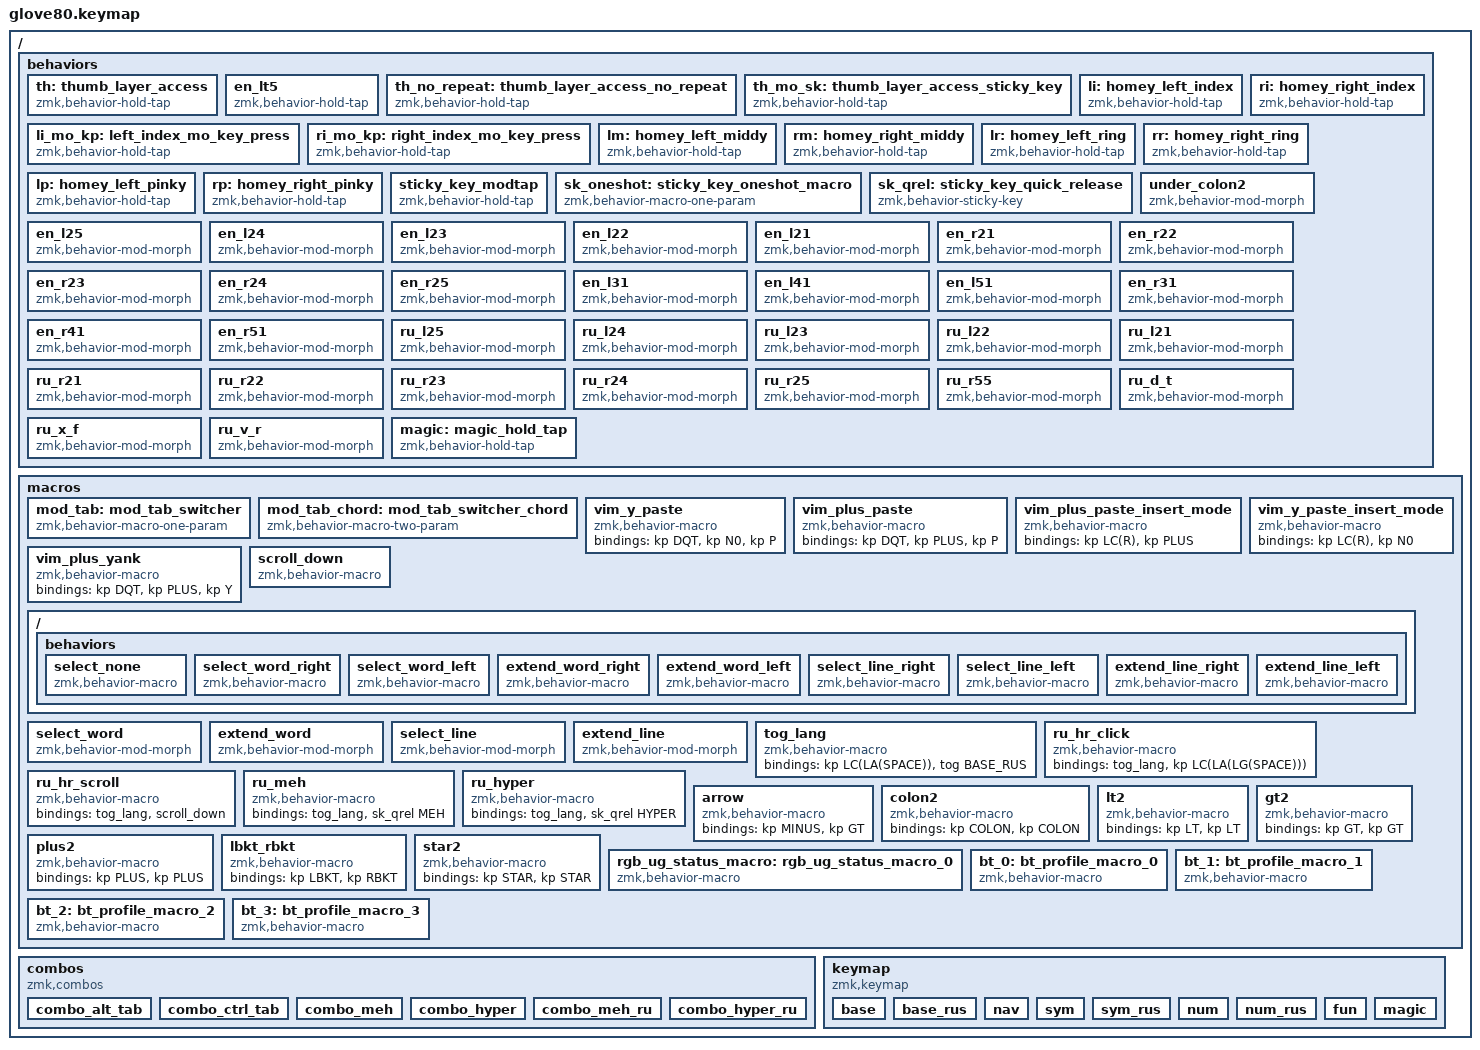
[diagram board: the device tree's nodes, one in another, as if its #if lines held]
/*
 * Copyright (c) 2020 The ZMK Contributors
 *
 * SPDX-License-Identifier: MIT
 */

#include <behaviors.dtsi>
#include <dt-bindings/zmk/keys.h>
#include <dt-bindings/zmk/bt.h>
#include <dt-bindings/zmk/ext_power.h>
#include <dt-bindings/zmk/outputs.h>
#include <dt-bindings/zmk/rgb.h>

#define HYPER LC(LS(LG(LALT)))
#define MEH LC(LG(LALT))

// layers
#define BASE 0
#define BASE_RUS 1
#define NAV 2
#define SYM 3
#define SYM_RUS 4
#define NUM 5
#define NUM_RUS 6
#define FUN 7
#define MAGIC 8

#ifndef OPERATING_SYSTEM
//#define OPERATING_SYSTEM 'L' // linux
#define OPERATING_SYSTEM 'M' // macos
//#define OPERATING_SYSTEM 'W' // windows
#endif
#if OPERATING_SYSTEM == 'M'
    #define _C      LG
    #define _A_TAB  LGUI
    #define _G_TAB  LALT
    #define _REDO   _C(LS(Z))
    #define _POWER  K_POWER
    #define _W      LA
    #define _HOME   _C(LEFT)
    #define _END    _C(RIGHT)
#else
    #define _C      LC
    #define _A_TAB  LALT
    #define _G_TAB  LGUI
    #define _REDO   _C(Y)
    #define _POWER  C_POWER
    #define _W      _C
    #define _HOME   HOME
    #define _END    END
#endif
#define _SLEEP      C_SLEEP
#if OPERATING_SYSTEM == 'W'
    #define _LOCK   LG(L)
#elif OPERATING_SYSTEM == 'M'
    #define _LOCK   _C(LC(Q))
#elif OPERATING_SYSTEM == 'L'
    #define _LOCK   K_LOCK
#endif
#define _UNDO       _C(Z)
#define _CUT        _C(X)
#define _COPY       _C(C)
#define _PASTE      _C(V)
#define _FIND       _C(F)
#define _FIND_NEXT  _C(G)
#define _FIND_PREV  _C(LS(G))


//
// The *_MOD specify which modifiers are used by home row mod keys.
//
#define RING_MOD LALT
#define INDEX_MOD LSHFT
#if OPERATING_SYSTEM == 'M'
  #define PINKY_MOD LCTRL
  #define MIDDY_MOD LGUI
#else
  #define PINKY_MOD LGUI
  #define MIDDY_MOD LCTRL
#endif

/* #define for key positions */
#define POS_LH_T1 52
#define POS_LH_T2 53
#define POS_LH_T3 54
#define POS_LH_T4 69
#define POS_LH_T5 70
#define POS_LH_T6 71
#define POS_LH_C1R2 15
#define POS_LH_C1R3 27
#define POS_LH_C1R4 39
#define POS_LH_C1R5 51
#define POS_LH_C2R1 4
#define POS_LH_C2R2 14
#define POS_LH_C2R3 26
#define POS_LH_C2R4 38
#define POS_LH_C2R5 50
#define POS_LH_C2R6 68
#define POS_LH_C3R1 3
#define POS_LH_C3R2 13
#define POS_LH_C3R3 25
#define POS_LH_C3R4 37
#define POS_LH_C3R5 49
#define POS_LH_C3R6 67
#define POS_LH_C4R1 2
#define POS_LH_C4R2 12
#define POS_LH_C4R3 24
#define POS_LH_C4R4 36
#define POS_LH_C4R5 48
#define POS_LH_C4R6 66
#define POS_LH_C5R1 1
#define POS_LH_C5R2 11
#define POS_LH_C5R3 23
#define POS_LH_C5R4 35
#define POS_LH_C5R5 47
#define POS_LH_C5R6 65
#define POS_LH_C6R1 0
#define POS_LH_C6R2 10
#define POS_LH_C6R3 22
#define POS_LH_C6R4 34
#define POS_LH_C6R5 46
#define POS_LH_C6R6 64
#define POS_RH_T1 57
#define POS_RH_T2 56
#define POS_RH_T3 55
#define POS_RH_T4 74
#define POS_RH_T5 73
#define POS_RH_T6 72
#define POS_RH_C1R2 16
#define POS_RH_C1R3 28
#define POS_RH_C1R4 40
#define POS_RH_C1R5 58
#define POS_RH_C2R1 5
#define POS_RH_C2R2 17
#define POS_RH_C2R3 29
#define POS_RH_C2R4 41
#define POS_RH_C2R5 59
#define POS_RH_C2R6 75
#define POS_RH_C3R1 6
#define POS_RH_C3R2 18
#define POS_RH_C3R3 30
#define POS_RH_C3R4 42
#define POS_RH_C3R5 60
#define POS_RH_C3R6 76
#define POS_RH_C4R1 7
#define POS_RH_C4R2 19
#define POS_RH_C4R3 31
#define POS_RH_C4R4 43
#define POS_RH_C4R5 61
#define POS_RH_C4R6 77
#define POS_RH_C5R1 8
#define POS_RH_C5R2 20
#define POS_RH_C5R3 32
#define POS_RH_C5R4 44
#define POS_RH_C5R5 62
#define POS_RH_C5R6 78
#define POS_RH_C6R1 9
#define POS_RH_C6R2 21
#define POS_RH_C6R3 33
#define POS_RH_C6R4 45
#define POS_RH_C6R5 63
#define POS_RH_C6R6 79

/ {

    //
    // TAPPING_RESOLUTION specifies the maximum speed at which the keyboard
    // confuses your taps as being holds when you type on home row mod keys.
    // When you lower this value, the same confusion should still occur; but
    // when you raise this value, you should be able to type normally again.
    //
    #define TAPPING_RESOLUTION 150

    //
    // HOMEY_HOLDING_TYPE defines the flavor of ZMK hold-tap behavior to use
    // for the pinky, ring, and middle fingers (which are assigned to Super,
    // Alt, and Ctrl respectively in the Miryoku system) on home row keys.
    //
    #define HOMEY_HOLDING_TYPE "tap-preferred"
    #define INDEX_HOLDING_TYPE HOMEY_HOLDING_TYPE
    #define MIDDY_HOLDING_TYPE HOMEY_HOLDING_TYPE
    #define RING_HOLDING_TYPE  HOMEY_HOLDING_TYPE
    #define PINKY_HOLDING_TYPE HOMEY_HOLDING_TYPE

    #define THUMB_HOLDING_TYPE "balanced"

    //
    // HOMEY_HOLDING_TIME defines how long you need to hold (milliseconds)
    // home row mod keys in order to send their modifiers to the computer
    // (i.e. "register" them) for mod-click mouse usage (e.g. Ctrl-Click).
    //
    #define HOMEY_HOLDING_TIME (TAPPING_RESOLUTION + 90)
    #define INDEX_HOLDING_TIME (TAPPING_RESOLUTION + 20)
    #define MIDDY_HOLDING_TIME (TAPPING_RESOLUTION + 60)
    #define RING_HOLDING_TIME  (TAPPING_RESOLUTION + 90)
    #define PINKY_HOLDING_TIME (TAPPING_RESOLUTION + 110)

    #define THUMB_HOLDING_TIME (TAPPING_RESOLUTION + 50)

    //
    // HOMEY_STREAK_DECAY defines how long you need to wait (milliseconds)
    // after typing before you can use home row mods again.  It prevents
    // unintended activation of home row mods when you're actively typing.
    //
    #define HOMEY_STREAK_DECAY TAPPING_RESOLUTION
    #define INDEX_STREAK_DECAY (TAPPING_RESOLUTION - 50)
    #define MIDDY_STREAK_DECAY HOMEY_STREAK_DECAY 
    #define RING_STREAK_DECAY  HOMEY_STREAK_DECAY 
    #define PINKY_STREAK_DECAY HOMEY_STREAK_DECAY 

    #define _STREAK_DECAY HOMEY_STREAK_DECAY 

    //
    // HOMEY_REPEAT_DECAY defines how much time you have left (milliseconds)
    // after tapping a key to hold it again in order to make it auto-repeat.
    //
    #define HOMEY_REPEAT_DECAY (TAPPING_RESOLUTION + 150)
    #define INDEX_REPEAT_DECAY HOMEY_REPEAT_DECAY
    #define MIDDY_REPEAT_DECAY HOMEY_REPEAT_DECAY
    #define RING_REPEAT_DECAY  HOMEY_REPEAT_DECAY
    #define PINKY_REPEAT_DECAY HOMEY_REPEAT_DECAY

    #define THUMB_REPEAT_DECAY (TAPPING_RESOLUTION + 150)

    //
    // Glove80 key positions index for positional hold-tap
    // - https://discord.com/channels/877392805654306816/937645688244826154/1066713913351221248
    // - https://media.discordapp.net/attachments/937645688244826154/1066713913133121556/image.png
    //
    // |------------------------|------------------------|
    // | LEFT_HAND_KEYS         |        RIGHT_HAND_KEYS |
    // |                        |                        |
    // |  0  1  2  3  4         |          5  6  7  8  9 |
    // | 10 11 12 13 14 15      |      16 17 18 19 20 21 |
    // | 22 23 24 25 26 27      |      28 29 30 31 32 33 |
    // | 34 35 36 37 38 39      |      40 41 42 43 44 45 |
    // | 46 47 48 49 50 51      |      58 59 60 61 62 63 |
    // | 64 65 66 67 68         |         75 76 77 78 79 |
    // |                69 52   |   57 74                |
    // |                 70 53  |  56 73                 |
    // |                  71 54 | 55 72                  |
    // |------------------------|------------------------|
    //
    #define LEFT_HAND_KEYS      \
          0  1  2  3  4         \
         10 11 12 13 14 15      \
         22 23 24 25 26 27      \
         34 35 36 37 38 39      \
         46 47 48 49 50 51      \
         64 65 66 67 68
    #define RIGHT_HAND_KEYS     \
                                           5  6  7  8  9 \
                                       16 17 18 19 20 21 \
                                       28 29 30 31 32 33 \
                                       40 41 42 43 44 45 \
                                       58 59 60 61 62 63 \
                                          75 76 77 78 79
    #define THUMB_KEYS          \
                        69 52       57 74                \
                         70 53     56 73                 \
                          71 54   55 72

    // Rus symbols
    #define COLON_RUS CARET
    #define DOT_RUS SLASH
    #define COMMA_RUS LS(SLASH)
    #define SEMI_RUS LS(N4)
    #define SQT_RUS RA(O)
    #define DQT_RUS LS(N2)
    #define GRAVE_RUS LC(RA(GRAVE))
    #define LBRC_RUS LS(RA(N9))
    #define RBRC_RUS LS(RA(N0))
    #define LBKT_RUS RA(GRAVE)
    #define RBKT_RUS LS(RA(GRAVE))
    #define QMARK_RUS LS(N7)
    #define AT_RUS RA(N2)
    #define HASH_RUS RA(N3)
    #define EXCL_RUS EXCL
    #define LT_RUS LS(RA(COMMA))
    #define GT_RUS LS(RA(DOT))
    #define AMPS_RUS RA(N7)
    #define CARET_RUS RA(N6)
    #define PIPE_RUS LS(RA(BSLH))
    #define PLUS_RUS PLUS
    #define DLLR_RUS RA(N4)
    #define MINUS_RUS MINUS
    #define STAR_RUS STAR
    #define SLASH_RUS LS(BSLH)
    #define TILDE_RUS D // did not find a way to get TILDE on rus
    #define PRCNT_RUS PRCNT
    #define BSLH_RUS BSLH
    #define EQUAL_RUS EQUAL
    #define UNDER_RUS UNDER
    #define LPAR_RUS LPAR
    #define RPAR_RUS RPAR
    #define MID_DASH_RUS RA(MINUS) 
    #define LON_DASH_RUS LS(RA(MINUS))
    #define LQT1_RUS RA(RBKT)
    #define RQT1_RUS LS(RA(RBKT))
    #define LQT2_RUS LS(RA(O))
    #define RQT2_RUS RA(LBKT)
    #define NO_RUS LS(N3)

    behaviors {
        th: thumb_layer_access {
            compatible = "zmk,behavior-hold-tap";
            flavor = THUMB_HOLDING_TYPE;
            tapping-term-ms = <THUMB_HOLDING_TIME>;
            quick-tap-ms = <THUMB_REPEAT_DECAY>; // enable repeat
            #binding-cells = <2>;
            bindings = <&mo>, <&kp>;
        };

        en_lt5: en_lt5 {
            compatible = "zmk,behavior-hold-tap";
            flavor = THUMB_HOLDING_TYPE;
            tapping-term-ms = <THUMB_HOLDING_TIME>;
            #binding-cells = <2>;
            bindings = <&mo>, <&under_colon2>;
        };

        th_no_repeat: thumb_layer_access_no_repeat {
            compatible = "zmk,behavior-hold-tap";
            flavor = THUMB_HOLDING_TYPE;
            tapping-term-ms = <THUMB_HOLDING_TIME>;
            #binding-cells = <2>;
            bindings = <&mo>, <&kp>;
        };

        th_mo_sk: thumb_layer_access_sticky_key {
            compatible = "zmk,behavior-hold-tap";
            flavor = THUMB_HOLDING_TYPE;
            tapping-term-ms = <THUMB_HOLDING_TIME>;
            #binding-cells = <2>;
            bindings = <&mo>, <&sk_qrel>;
        };

        li: homey_left_index {
            compatible = "zmk,behavior-hold-tap";
            flavor = INDEX_HOLDING_TYPE;
            hold-trigger-key-positions = <RIGHT_HAND_KEYS THUMB_KEYS>;
            hold-trigger-on-release; // wait for other home row mods
            tapping-term-ms = <INDEX_HOLDING_TIME>;
            quick-tap-ms = <INDEX_REPEAT_DECAY>;
            require-prior-idle-ms = <INDEX_STREAK_DECAY>;
            #binding-cells = <2>;
            bindings = <&kp>, <&kp>;
        };

        li_mo_kp: left_index_mo_key_press {
            compatible = "zmk,behavior-hold-tap";
            flavor = INDEX_HOLDING_TYPE;
            hold-trigger-key-positions = <RIGHT_HAND_KEYS THUMB_KEYS>;
            hold-trigger-on-release; // wait for other home row mods
            tapping-term-ms = <INDEX_HOLDING_TIME>;
            quick-tap-ms = <INDEX_REPEAT_DECAY>;
            require-prior-idle-ms = <INDEX_STREAK_DECAY>;
            #binding-cells = <2>;
            bindings = <&mo>, <&kp>;
        };

        ri: homey_right_index {
            compatible = "zmk,behavior-hold-tap";
            flavor = INDEX_HOLDING_TYPE;
            hold-trigger-key-positions = <LEFT_HAND_KEYS THUMB_KEYS>;
            hold-trigger-on-release; // wait for other home row mods
            tapping-term-ms = <INDEX_HOLDING_TIME>;
            quick-tap-ms = <INDEX_REPEAT_DECAY>;
            require-prior-idle-ms = <INDEX_STREAK_DECAY>;
            #binding-cells = <2>;
            bindings = <&kp>, <&kp>;
        };

        ri_mo_kp: right_index_mo_key_press {
            compatible = "zmk,behavior-hold-tap";
            flavor = INDEX_HOLDING_TYPE;
            hold-trigger-key-positions = <LEFT_HAND_KEYS THUMB_KEYS>;
            hold-trigger-on-release; // wait for other home row mods
            tapping-term-ms = <INDEX_HOLDING_TIME>;
            quick-tap-ms = <INDEX_REPEAT_DECAY>;
            require-prior-idle-ms = <INDEX_STREAK_DECAY>;
            #binding-cells = <2>;
            bindings = <&mo>, <&kp>;
        };

        lm: homey_left_middy {
            compatible = "zmk,behavior-hold-tap";
            flavor = MIDDY_HOLDING_TYPE;
            hold-trigger-key-positions = <RIGHT_HAND_KEYS THUMB_KEYS>;
            hold-trigger-on-release; // wait for other home row mods
            tapping-term-ms = <MIDDY_HOLDING_TIME>;
            quick-tap-ms = <MIDDY_REPEAT_DECAY>;
            require-prior-idle-ms = <MIDDY_STREAK_DECAY>;
            #binding-cells = <2>;
            bindings = <&kp>, <&kp>;
        };

        rm: homey_right_middy {
            compatible = "zmk,behavior-hold-tap";
            flavor = MIDDY_HOLDING_TYPE;
            hold-trigger-key-positions = <LEFT_HAND_KEYS THUMB_KEYS>;
            hold-trigger-on-release; // wait for other home row mods
            tapping-term-ms = <MIDDY_HOLDING_TIME>;
            quick-tap-ms = <MIDDY_REPEAT_DECAY>;
            require-prior-idle-ms = <MIDDY_STREAK_DECAY>;
            #binding-cells = <2>;
            bindings = <&kp>, <&kp>;
        };

        lr: homey_left_ring {
            compatible = "zmk,behavior-hold-tap";
            flavor = RING_HOLDING_TYPE;
            hold-trigger-key-positions = <RIGHT_HAND_KEYS THUMB_KEYS>;
            hold-trigger-on-release; // wait for other home row mods
            tapping-term-ms = <RING_HOLDING_TIME>;
            quick-tap-ms = <RING_REPEAT_DECAY>;
            require-prior-idle-ms = <RING_STREAK_DECAY>;
            #binding-cells = <2>;
            bindings = <&kp>, <&kp>;
        };

        rr: homey_right_ring {
            compatible = "zmk,behavior-hold-tap";
            flavor = RING_HOLDING_TYPE;
            hold-trigger-key-positions = <LEFT_HAND_KEYS THUMB_KEYS>;
            hold-trigger-on-release; // wait for other home row mods
            tapping-term-ms = <RING_HOLDING_TIME>;
            quick-tap-ms = <RING_REPEAT_DECAY>;
            require-prior-idle-ms = <RING_STREAK_DECAY>;
            #binding-cells = <2>;
            bindings = <&kp>, <&kp>;
        };

        lp: homey_left_pinky {
            compatible = "zmk,behavior-hold-tap";
            flavor = PINKY_HOLDING_TYPE;
            hold-trigger-key-positions = <RIGHT_HAND_KEYS THUMB_KEYS>;
            hold-trigger-on-release; // wait for other home row mods
            tapping-term-ms = <PINKY_HOLDING_TIME>;
            quick-tap-ms = <PINKY_REPEAT_DECAY>;
            require-prior-idle-ms = <PINKY_STREAK_DECAY>;
            #binding-cells = <2>;
            bindings = <&kp>, <&kp>;
            // shift forgiveness
            //hold-while-undecided; // requires 24.08-beta1 or newer firmware, if the firmware is older, it fails
            retro-tap; // tap on standalone hold
        };

        rp: homey_right_pinky {
            compatible = "zmk,behavior-hold-tap";
            flavor = PINKY_HOLDING_TYPE;
            hold-trigger-key-positions = <LEFT_HAND_KEYS THUMB_KEYS>;
            hold-trigger-on-release; // wait for other home row mods
            tapping-term-ms = <PINKY_HOLDING_TIME>;
            quick-tap-ms = <PINKY_REPEAT_DECAY>;
            require-prior-idle-ms = <PINKY_STREAK_DECAY>;
            #binding-cells = <2>;
            bindings = <&kp>, <&kp>;
            // shift forgiveness
            //hold-while-undecided; // requires 24.08-beta1 or newer firmware
            retro-tap; // tap on standalone hold
        };

        //////////////////////////////////////////////////////////////////////////
        //
        // &sk (sticky key) variant that is truly one-shot
        //
        //////////////////////////////////////////////////////////////////////////

        //
        // STICKY_1SHOT_DECAY defines how much time you have left (milliseconds)
        // after tapping a sticky key before it expires (won't apply to next tap).
        //
        #ifndef STICKY_1SHOT_DECAY
        #define STICKY_1SHOT_DECAY 500
        #endif

        //
        // STICKY_HOLDING_TIME defines how long you need to hold (milliseconds)
        // sticky one-shot keys in order to trigger their hold (not tap) action.
        //
        #ifndef STICKY_HOLDING_TIME
        #define STICKY_HOLDING_TIME (TAPPING_RESOLUTION + 50)
        #endif

        sticky_key_modtap: sticky_key_modtap {
            compatible = "zmk,behavior-hold-tap";
            flavor = "tap-preferred";
            tapping-term-ms = <STICKY_HOLDING_TIME>;
            #binding-cells = <2>;
            bindings = <&kp>, <&sk_oneshot>;
        };
        sk_oneshot: sticky_key_oneshot_macro {
            compatible = "zmk,behavior-macro-one-param";
            wait-ms = <0>;
            tap-ms = <0>;
            #binding-cells = <1>;
            bindings
                = <&macro_param_1to1>
                , <&macro_tap &sk_qrel MACRO_PLACEHOLDER>
                ;
        };
        sk_qrel: sticky_key_quick_release {
            compatible = "zmk,behavior-sticky-key";
            #binding-cells = <1>;
            bindings = <&kp>;
            release-after-ms = <STICKY_1SHOT_DECAY>;
            quick-release;
            ignore-modifiers;
        };


        //
        // Custom shifted pairs for the Engram layout
        // - https://engram.dev/
        // - https://sunaku.github.io/engram-keyboard-layout.html
        //

        under_colon2: under_colon2 {
            compatible = "zmk,behavior-mod-morph";
            #binding-cells = <0>;
            bindings = <&kp UNDER>, <&colon2>;
            mods = <(MOD_LSFT|MOD_RSFT)>;
        };

        en_l25: en_l25 {
            compatible = "zmk,behavior-mod-morph";
            #binding-cells = <0>;
            bindings = <&kp LT>, <&kp CARET>;
            mods = <(MOD_LSFT|MOD_RSFT)>;
        };

        en_l24: en_l24 {
            compatible = "zmk,behavior-mod-morph";
            #binding-cells = <0>;
            bindings = <&kp LPAR>, <&kp AT>;
            mods = <(MOD_LSFT|MOD_RSFT)>;
        };

        en_l23: en_l23 {
            compatible = "zmk,behavior-mod-morph";
            #binding-cells = <0>;
            bindings = <&kp RPAR>, <&kp HASH>;
            mods = <(MOD_LSFT|MOD_RSFT)>;
        };

        en_l22: en_l22 {
            compatible = "zmk,behavior-mod-morph";
            #binding-cells = <0>;
            bindings = <&kp GT>, <&kp BSLH>;
            mods = <(MOD_LSFT|MOD_RSFT)>;
        };

        en_l21: en_l21 {
            compatible = "zmk,behavior-mod-morph";
            #binding-cells = <0>;
            bindings = <&kp PIPE>, <&star2>;
            mods = <(MOD_LSFT|MOD_RSFT)>;
        };

        en_r21: en_r21 {
            compatible = "zmk,behavior-mod-morph";
            #binding-cells = <0>;
            bindings = <&kp AMPS>, <&plus2>;
            mods = <(MOD_LSFT|MOD_RSFT)>;
        };

        en_r22: en_r22 {
            compatible = "zmk,behavior-mod-morph";
            #binding-cells = <0>;
            bindings = <&kp LBKT>, <&kp PRCNT>;
            mods = <(MOD_LSFT|MOD_RSFT)>;
        };

        en_r23: en_r23 {
            compatible = "zmk,behavior-mod-morph";
            #binding-cells = <0>;
            bindings = <&kp LBRC>, <&kp TILDE>;
            mods = <(MOD_LSFT|MOD_RSFT)>;
        };

        en_r24: en_r24 {
            compatible = "zmk,behavior-mod-morph";
            #binding-cells = <0>;
            bindings = <&kp RBRC>, <&kp GRAVE>;
            mods = <(MOD_LSFT|MOD_RSFT)>;
        };

        en_r25: en_r25 {
            compatible = "zmk,behavior-mod-morph";
            #binding-cells = <0>;
            bindings = <&kp RBKT>, <&kp DLLR>;
            mods = <(MOD_LSFT|MOD_RSFT)>;
        };

        en_l31: en_l31 {
            compatible = "zmk,behavior-mod-morph";
            #binding-cells = <0>;
            bindings = <&kp SLASH>, <&kp STAR>;
            mods = <(MOD_LSFT|MOD_RSFT)>;
        };

        en_l41: en_l41 {
            compatible = "zmk,behavior-mod-morph";
            #binding-cells = <0>;
            bindings = <&kp COMMA>, <&kp SEMI>;
            mods = <(MOD_LSFT|MOD_RSFT)>;
        };

        en_l51: en_l51 {
            compatible = "zmk,behavior-mod-morph";
            #binding-cells = <0>;
            bindings = <&kp QMARK>, <&kp EXCL>;
            mods = <(MOD_LSFT|MOD_RSFT)>;
        };

        en_r31: en_r31 {
            compatible = "zmk,behavior-mod-morph";
            #binding-cells = <0>;
            bindings = <&kp MINUS>, <&kp PLUS>;
            mods = <(MOD_LSFT|MOD_RSFT)>;
        };

        en_r41: en_r41 {
            compatible = "zmk,behavior-mod-morph";
            #binding-cells = <0>;
            bindings = <&kp DOT>, <&kp COLON>;
            mods = <(MOD_LSFT|MOD_RSFT)>;
        };

        en_r51: en_r51 {
            compatible = "zmk,behavior-mod-morph";
            #binding-cells = <0>;
            bindings = <&kp SQT>, <&kp DQT>;
            mods = <(MOD_LSFT|MOD_RSFT)>;
        };

        ru_l25: ru_l25 {
            compatible = "zmk,behavior-mod-morph";
            #binding-cells = <0>;
            bindings = <&kp HASH_RUS>, <&kp AT_RUS>;
            mods = <(MOD_LSFT|MOD_RSFT)>;
        };

        ru_l24: ru_l24 {
            compatible = "zmk,behavior-mod-morph";
            #binding-cells = <0>;
            bindings = <&kp LPAR_RUS>, <&kp PRCNT_RUS>;
            mods = <(MOD_LSFT|MOD_RSFT)>;
        };

        ru_l23: ru_l23 {
            compatible = "zmk,behavior-mod-morph";
            #binding-cells = <0>;
            bindings = <&kp RPAR_RUS>, <&kp NO_RUS>;
            mods = <(MOD_LSFT|MOD_RSFT)>;
        };

        ru_l22: ru_l22 {
            compatible = "zmk,behavior-mod-morph";
            #binding-cells = <0>;
            bindings = <&kp QMARK_RUS>, <&kp EXCL_RUS>;
            mods = <(MOD_LSFT|MOD_RSFT)>;
        };

        ru_l21: ru_l21 {
            compatible = "zmk,behavior-mod-morph";
            #binding-cells = <0>;
            bindings = <&kp SLASH_RUS>, <&kp STAR_RUS>;
            mods = <(MOD_LSFT|MOD_RSFT)>;
        };

        ru_r21: ru_r21 {
            compatible = "zmk,behavior-mod-morph";
            #binding-cells = <0>;
            bindings = <&kp MINUS_RUS>, <&kp PLUS_RUS>;
            mods = <(MOD_LSFT|MOD_RSFT)>;
        };

        ru_r22: ru_r22 {
            compatible = "zmk,behavior-mod-morph";
            #binding-cells = <0>;
            bindings = <&kp COLON_RUS>, <&kp SEMI_RUS>;
            mods = <(MOD_LSFT|MOD_RSFT)>;
        };

        ru_r23: ru_r23 {
            compatible = "zmk,behavior-mod-morph";
            #binding-cells = <0>;
            bindings = <&kp LQT1_RUS>, <&kp LQT2_RUS>;
            mods = <(MOD_LSFT|MOD_RSFT)>;
        };

        ru_r24: ru_r24 {
            compatible = "zmk,behavior-mod-morph";
            #binding-cells = <0>;
            bindings = <&kp RQT1_RUS>, <&kp RQT2_RUS>;
            mods = <(MOD_LSFT|MOD_RSFT)>;
        };

        ru_r25: ru_r25 {
            compatible = "zmk,behavior-mod-morph";
            #binding-cells = <0>;
            bindings = <&kp N0>, <&kp HASH_RUS>;
            mods = <(MOD_LSFT|MOD_RSFT)>;
        };

        ru_r55: ru_r55 {
            compatible = "zmk,behavior-mod-morph";
            #binding-cells = <0>;
            bindings = <&kp COMMA_RUS>, <&kp SEMI_RUS>;
            mods = <(MOD_LSFT|MOD_RSFT)>;
        };

        ru_d_t: ru_d_t {
            compatible = "zmk,behavior-mod-morph";
            #binding-cells = <0>;
            bindings = <&kp D>, <&kp T>;
            mods = <(MOD_LGUI|MOD_RGUI|MOD_LCTL|MOD_RCTL)>;
            keep-mods = <(MOD_LGUI|MOD_RGUI|MOD_LCTL|MOD_RCTL)>;
        };

        ru_x_f: ru_x_f {
            compatible = "zmk,behavior-mod-morph";
            #binding-cells = <0>;
            bindings = <&kp X>, <&kp F>;
            mods = <(MOD_LGUI|MOD_RGUI|MOD_LCTL|MOD_RCTL)>;
            keep-mods = <(MOD_LGUI|MOD_RGUI|MOD_LCTL|MOD_RCTL)>;
        };

        ru_v_r: ru_v_r {
            compatible = "zmk,behavior-mod-morph";
            #binding-cells = <0>;
            bindings = <&kp V>, <&kp R>;
            mods = <(MOD_LGUI|MOD_RGUI|MOD_LCTL|MOD_RCTL)>;
            keep-mods = <(MOD_LGUI|MOD_RGUI|MOD_LCTL|MOD_RCTL)>;
        };

        magic: magic_hold_tap {
            compatible = "zmk,behavior-hold-tap";
            label = "MAGIC_HOLD_TAP";
            #binding-cells = <2>;
            flavor = "tap-preferred";
            tapping-term-ms = <200>;
            bindings = <&mo>, <&rgb_ug_status_macro>;
        };
    };

    macros {
        //
        // Mod+Tab application switcher - hold this down to keep menu open
        //
        mod_tab: mod_tab_switcher {
            compatible = "zmk,behavior-macro-one-param";
            wait-ms = <0>;
            tap-ms = <0>;
            #binding-cells = <1>;
            bindings
                = <&macro_param_1to1>
                , <&macro_press &kp MACRO_PLACEHOLDER>
                , <&macro_tap &kp TAB>
                , <&macro_pause_for_release>
                , <&macro_param_1to1>
                , <&macro_release &kp MACRO_PLACEHOLDER>
                ;
        };
        mod_tab_chord: mod_tab_switcher_chord {
            compatible = "zmk,behavior-macro-two-param";
            wait-ms = <0>;
            tap-ms = <0>;
            #binding-cells = <2>;
            bindings
                = <&macro_param_2to1>
                , <&macro_press &mo MACRO_PLACEHOLDER>
                , <&macro_param_1to1>
                , <&macro_press &mod_tab MACRO_PLACEHOLDER>
                , <&macro_pause_for_release>
                , <&macro_param_1to1>
                , <&macro_release &mod_tab MACRO_PLACEHOLDER>
                , <&macro_param_2to1>
                , <&macro_release &mo MACRO_PLACEHOLDER>
                ;
        };
       
        vim_y_paste: vim_y_paste {
            compatible = "zmk,behavior-macro";
            #binding-cells = <0>;
            bindings = <&kp DQT &kp N0 &kp P>;
        };

        vim_plus_paste: vim_plus_paste {
            compatible = "zmk,behavior-macro";
            #binding-cells = <0>;
            bindings = <&kp DQT &kp PLUS &kp P>;
        };

        vim_plus_paste_insert_mode: vim_plus_paste_insert_mode {
            compatible = "zmk,behavior-macro";
            #binding-cells = <0>;
            bindings = <&kp LC(R) &kp PLUS>;
        };

        vim_y_paste_insert_mode: vim_y_paste_insert_mode {
            compatible = "zmk,behavior-macro";
            #binding-cells = <0>;
            bindings = <&kp LC(R) &kp N0>;
        };

        vim_plus_yank: vim_plus_yank {
            compatible = "zmk,behavior-macro";
            #binding-cells = <0>;
            bindings = <&kp DQT &kp PLUS &kp Y>;
        };

        scroll_down: scroll_down {
            compatible = "zmk,behavior-macro";
            wait-ms = <20>;
            #binding-cells = <0>;
            bindings = <&kp LC(LA(LG(SEMI))) &kp DOWN>;
        };

        //////////////////////////////////////////////////////////////////////////
        //
        // Approximation of Pascal Getreuer's Select Word macro from QMK
        // - https://getreuer.info/posts/keyboards/select-word/index.html
        //
        //////////////////////////////////////////////////////////////////////////

        //
        // SELECT_WORD_DELAY defines how long the macro waits (milliseconds)
        // after moving the cursor before it selects a word.  A larger delay
        // may allow the macro to move to the next word upon each invocation.
        //
        #ifndef SELECT_WORD_DELAY
        #define SELECT_WORD_DELAY 1
        #endif

        ZMK_MACRO(select_none,
            wait-ms = <SELECT_WORD_DELAY>;
            tap-ms = <SELECT_WORD_DELAY>;
            bindings = <&kp DOWN &kp UP &kp RIGHT &kp LEFT>;
        )

        //
        // select a word (jumps to next word upon each successive invocation)
        //
        select_word: select_word {
            compatible = "zmk,behavior-mod-morph";
            #binding-cells = <0>;
            bindings = <&select_word_right>, <&select_word_left>;
            mods = <(MOD_LSFT|MOD_RSFT)>;
        };
        ZMK_MACRO(select_word_right,
            wait-ms = <SELECT_WORD_DELAY>;
            tap-ms = <SELECT_WORD_DELAY>;
            bindings = <&kp _W(RIGHT) &kp _W(LEFT) &kp _W(LS(RIGHT))>;
        )
        ZMK_MACRO(select_word_left,
            wait-ms = <SELECT_WORD_DELAY>;
            tap-ms = <SELECT_WORD_DELAY>;
            bindings = <&kp _W(LEFT) &kp _W(RIGHT) &kp _W(LS(LEFT))>;
        )

        //
        // extend current selection by one word
        //
        extend_word: extend_word {
            compatible = "zmk,behavior-mod-morph";
            #binding-cells = <0>;
            bindings = <&extend_word_right>, <&extend_word_left>;
            mods = <(MOD_LSFT|MOD_RSFT)>;
        };
        ZMK_MACRO(extend_word_right,
            wait-ms = <SELECT_WORD_DELAY>;
            tap-ms = <SELECT_WORD_DELAY>;
            bindings = <&kp _W(LS(RIGHT))>;
        )
        ZMK_MACRO(extend_word_left,
            wait-ms = <SELECT_WORD_DELAY>;
            tap-ms = <SELECT_WORD_DELAY>;
            bindings = <&kp _W(LS(LEFT))>;
        )

        //
        // select current line
        //
        select_line: select_line {
            compatible = "zmk,behavior-mod-morph";
            #binding-cells = <0>;
            bindings = <&select_line_right>, <&select_line_left>;
            mods = <(MOD_LSFT|MOD_RSFT)>;
        };
        ZMK_MACRO(select_line_right,
            wait-ms = <SELECT_WORD_DELAY>;
            tap-ms = <SELECT_WORD_DELAY>;
            bindings = <&kp _HOME &kp LS(_END)>;
        )
        ZMK_MACRO(select_line_left,
            wait-ms = <SELECT_WORD_DELAY>;
            tap-ms = <SELECT_WORD_DELAY>;
            bindings = <&kp _END &kp LS(_HOME)>;
        )

        //
        // extend current selection by one line
        //
        extend_line: extend_line {
            compatible = "zmk,behavior-mod-morph";
            #binding-cells = <0>;
            bindings = <&extend_line_right>, <&extend_line_left>;
            mods = <(MOD_LSFT|MOD_RSFT)>;
        };
        ZMK_MACRO(extend_line_right,
            wait-ms = <SELECT_WORD_DELAY>;
            tap-ms = <SELECT_WORD_DELAY>;
            bindings = <&kp LS(DOWN) &kp LS(_END)>;
        )
        ZMK_MACRO(extend_line_left,
            wait-ms = <SELECT_WORD_DELAY>;
            tap-ms = <SELECT_WORD_DELAY>;
            bindings = <&kp LS(UP) &kp LS(_HOME)>;
        )

        tog_lang: tog_lang {
            compatible = "zmk,behavior-macro";
            #binding-cells = <0>;
            bindings = <&kp LC(LA(SPACE)) &tog BASE_RUS>;
        };

        ru_hr_click: ru_hr_click {
            compatible = "zmk,behavior-macro";
            #binding-cells = <0>;
            bindings = <&tog_lang &kp LC(LA(LG(SPACE)))>;
        };

        ru_hr_scroll: ru_hr_scroll{
            compatible = "zmk,behavior-macro";
            #binding-cells = <0>;
            bindings = <&tog_lang &scroll_down>;
        };

        ru_meh: ru_meh {
            compatible = "zmk,behavior-macro";
            #binding-cells = <0>;
            bindings = <&tog_lang &sk_qrel MEH>;
        };

        ru_hyper: ru_hyper {
            compatible = "zmk,behavior-macro";
            #binding-cells = <0>;
            bindings = <&tog_lang &sk_qrel HYPER>;
        };

        arrow: arrow {
            compatible = "zmk,behavior-macro";
            #binding-cells = <0>;
            bindings = <&kp MINUS &kp GT>;
        };

        colon2: colon2 {
            compatible = "zmk,behavior-macro";
            #binding-cells = <0>;
            bindings = <&kp COLON &kp COLON>;
        };

        lt2: lt2 {
            compatible = "zmk,behavior-macro";
            #binding-cells = <0>;
            bindings = <&kp LT &kp LT>;
        };

        gt2: gt2 {
            compatible = "zmk,behavior-macro";
            #binding-cells = <0>;
            bindings = <&kp GT &kp GT>;
        };

        plus2: plus2 {
            compatible = "zmk,behavior-macro";
            #binding-cells = <0>;
            bindings = <&kp PLUS &kp PLUS>;
        };

        lbkt_rbkt: lbkt_rbkt {
            compatible = "zmk,behavior-macro";
            #binding-cells = <0>;
            bindings = <&kp LBKT &kp RBKT>;
        };

        star2: star2 {
            compatible = "zmk,behavior-macro";
            #binding-cells = <0>;
            bindings = <&kp STAR &kp STAR>;
        };

        rgb_ug_status_macro: rgb_ug_status_macro_0 {
            label = "RGB_UG_STATUS";
            compatible = "zmk,behavior-macro";
            #binding-cells = <0>;
            bindings
                = <&rgb_ug RGB_STATUS>;
        };

        bt_0: bt_profile_macro_0 {
            label = "BT_0";
            compatible = "zmk,behavior-macro";
            #binding-cells = <0>;
            bindings
                = <&out OUT_BLE>,
                  <&bt BT_SEL 0>;
        };

        bt_1: bt_profile_macro_1 {
            label = "BT_1";
            compatible = "zmk,behavior-macro";
            #binding-cells = <0>;
            bindings
                = <&out OUT_BLE>,
                  <&bt BT_SEL 1>;
        };

        bt_2: bt_profile_macro_2 {
            label = "BT_2";
            compatible = "zmk,behavior-macro";
            #binding-cells = <0>;
            bindings
                = <&out OUT_BLE>,
                  <&bt BT_SEL 2>;
        };

        bt_3: bt_profile_macro_3 {
            label = "BT_3";
            compatible = "zmk,behavior-macro";
            #binding-cells = <0>;
            bindings
                = <&out OUT_BLE>,
                  <&bt BT_SEL 3>;
        };
    };

    combos {
        compatible = "zmk,combos";

        //
        // COMBO_FIRING_DECAY defines how much time you have left (milliseconds)
        // after pressing the first key in a ZMK combo to finish the whole chord.
        //
        #ifndef COMBO_FIRING_DECAY
        #define COMBO_FIRING_DECAY 50
        #endif
        
        combo_alt_tab {
            timeout-ms = <COMBO_FIRING_DECAY>;
            key-positions = <POS_LH_T4 POS_LH_T1>;
            bindings = <&mod_tab_chord _A_TAB NAV>;
            layers = <BASE BASE_RUS NAV>;
        };
        combo_ctrl_tab {
            timeout-ms = <COMBO_FIRING_DECAY>;
            key-positions = <POS_LH_T5 POS_LH_T4>;
            bindings = <&mod_tab_chord LCTL NAV>;
            layers = <BASE BASE_RUS NAV>;
        };

        combo_meh {
            timeout-ms = <COMBO_FIRING_DECAY>;
            key-positions = <POS_RH_T4 POS_RH_T1>;
            bindings = <&sk_qrel MEH>;
            layers = <BASE>;
        };
        combo_hyper {
            timeout-ms = <COMBO_FIRING_DECAY>;
            key-positions = <POS_RH_T4 POS_RH_T5>;
            bindings = <&sk_qrel HYPER>;
            layers = <BASE>;
        };

        combo_meh_ru {
            timeout-ms = <COMBO_FIRING_DECAY>;
            key-positions = <POS_RH_T4 POS_RH_T1>;
            bindings = <&ru_meh>;
            layers = <BASE_RUS>;
        };
        combo_hyper_ru {
            timeout-ms = <COMBO_FIRING_DECAY>;
            key-positions = <POS_RH_T4 POS_RH_T5>;
            bindings = <&ru_hyper>;
            layers = <BASE_RUS>;
        };
    };

    keymap {
        compatible = "zmk,keymap";

        base {
            bindings = <
            &kp F1                   &kp F2                  &none                 &none                   &none                                                                                                                                                                  &none                    &none                    &none                  &none                       &none
            &none                    &en_l25                 &en_l24               &en_l23                 &en_l22                 &en_l21                                                                                                                          &en_r21       &en_r22                  &en_r23                  &en_r24                &en_r25                     &none
            &kp N0                   &kp Q                   &kp W                 &kp D                   &kp L                   &en_l31                                                                                                                          &en_r31       &kp U                    &kp O                    &kp Y                  &kp Z                       &kp N1
            &kp V                    &kp N                   &kp S                 &kp T                   &kp H                   &en_l41                                                                                                                          &en_r41       &kp A                    &kp E                    &kp I                  &kp C                       &kp B
            &tog_lang                &kp P                   &kp F                 &kp M                   &kp R                   &en_l51     &th FUN ESC              &kp EQUAL      &none                  &caps_word    &kp TAB        &kp RET                  &en_r51       &kp K                    &kp J                    &kp X                  &kp G                       &caps_word
            &magic MAGIC 0           &sk_qrel PINKY_MOD      &sk_qrel RING_MOD     &sk_qrel MIDDY_MOD      &sk_qrel INDEX_MOD                  &th_mo_sk NAV BSPC       &en_lt5 NUM 0  &kp LC(LA(LG(SPACE)))  &scroll_down  &key_repeat    &th_no_repeat SYM SPACE                &sk_qrel INDEX_MOD       &sk_qrel MIDDY_MOD       &sk_qrel RING_MOD      &sk_qrel PINKY_MOD          &magic MAGIC 0
            >;
        };

        base_rus {
            bindings = <
            &none                    &none                   &none                 &none                   &none                                                                                                                          &none                  &none                     &none                    &none                       &none
            &none                    &ru_l25                 &ru_l24               &ru_l23                 &ru_l22                 &ru_l21                                                                                      &ru_r21   &ru_r22                &ru_r23                   &ru_r24                  &kp RBKT                    &none
            &none                    &kp Q                   &kp W                 &kp E                   &kp R                   &kp T                                                                                        &kp Y     &kp U                  &kp I                     &kp O                    &kp P                       &kp LBKT
            &kp GRAVE                &kp A                   &kp S                 &ru_d_t                 &kp F                   &kp G                                                                                        &kp H     &kp J                  &kp K                     &kp L                    &kp SEMI                    &kp SQT
            &trans                   &kp Z                   &ru_x_f               &kp C                   &ru_v_r                 &kp B   &trans  &trans  &trans          &trans        &trans  &trans                         &kp N     &kp M                  &kp COMMA                 &kp DOT                  &kp SLASH                   &trans
            &magic MAGIC 0           &trans                  &trans                &trans                  &trans                          &trans  &trans  &ru_hr_click    &ru_hr_scroll &trans  &th_no_repeat SYM_RUS SPACE              &trans                 &trans                    &trans                   &trans                      &magic MAGIC 0
            >;
        };

        nav {
            bindings = <
            &none          &none               &none              &none               &none                                                                                                                                 &none                    &none                    &none                        &none      &none
            &none          &none               &kp ESC            &kp LS(TAB)         &kp DEL             &kp _C(LS(C))                                                                                    &none            &kp _C(LA(LEFT))         &kp HOME                 &kp _C(LA(RIGHT))            &none      &none
            &none          &kp RET             &kp SPACE          &kp TAB             &kp BSPC            &kp _CUT                                                                                         &kp _C(R)        &kp _C(LS(LBKT))         &kp UP                   &kp _C(LS(RBKT))             &kp _C(W)  &kp Q
            &none          &sk_qrel PINKY_MOD  &sk_qrel RING_MOD  &sk_qrel MIDDY_MOD  &sk_qrel INDEX_MOD  &kp _COPY                                                                                        &vim_plus_yank   &kp LEFT                 &kp DOWN                 &kp RIGHT                    &none      &none
            &none          &kp _C(A)           &select_line       &select_word        &kp _FIND           &kp _PASTE   &mod_tab _A_TAB &none          &none     &select_none  &extend_line  &extend_word   &vim_plus_paste  &kp _HOME                &kp PG_UP                &kp PG_DN                    &kp _END   &none
            &kp LG(S)      &kp _UNDO           &kp _REDO          &kp _FIND_PREV      &kp _FIND_NEXT                   &none           &mod_tab LCTL  &none     &kp _C(A)     &select_line  &select_word                    &vim_y_paste             &vim_y_paste_insert_mode &vim_plus_paste_insert_mode  &none      &none
            >;
        };

        sym {
            bindings = <
            &none          &none          &none         &none          &none                                                                                                 &none           &none           &none          &none           &none
            &none          &kp GRAVE      &kp LPAR      &kp RPAR       &kp SEMI     &kp COMMA                                                                       &none    &none           &none           &none          &none           &none
            &kp EXCL       &kp LBRC       &kp SQT       &kp DQT        &kp RBRC     &kp QMARK                                                                       &none    &kp INDEX_MOD   &kp MIDDY_MOD   &kp RING_MOD   &kp PINKY_MOD   &none
            &kp HASH       &kp CARET      &kp EQUAL     &kp UNDER      &kp DLLR     &kp STAR                                                                        &none    &kp SPACE       &kp RET         &kp BSPC       &kp TAB         &none
            &kp TILDE      &kp LT         &kp PIPE      &kp MINUS      &kp GT       &kp SLASH      &kp BSLH   &kp DOT    &kp STAR   &none     &none      &none      &none    &none           &none           &kp DEL        &none           &none
            &kp AT         &kp AMPS       &kp LBKT      &kp RBKT       &kp PLUS                    &kp PRCNT  &kp COLON  &kp SEMI   &none     &none      &none               &none           &none           &none          &none           &none
            >;
        };

        sym_rus {
            bindings = <
            &none          &none              &none             &none              &none                                                                                                                     &none           &none           &none          &none           &none
            &none          &kp GRAVE_RUS      &kp LPAR_RUS      &kp RPAR_RUS       &kp SEMI_RUS     &kp COMMA_RUS                                                                                   &none    &none           &none           &none          &none           &none
            &kp EXCL_RUS   &kp LBRC_RUS       &kp SQT_RUS       &kp DQT_RUS        &kp RBRC_RUS     &kp QMARK_RUS                                                                                   &none    &kp INDEX_MOD   &kp MIDDY_MOD   &kp RING_MOD   &kp PINKY_MOD   &none
            &kp HASH_RUS   &kp CARET_RUS      &kp EQUAL_RUS     &kp UNDER_RUS      &kp DLLR_RUS     &kp STAR_RUS                                                                                    &none    &kp SPACE       &kp RET         &kp BSPC       &kp TAB         &none
            &kp TILDE_RUS  &kp LT_RUS         &kp PIPE_RUS      &kp MINUS_RUS      &kp GT_RUS       &kp SLASH_RUS      &kp BSLH_RUS   &kp DOT_RUS    &kp STAR_RUS   &none     &none      &none      &none    &none           &none           &kp DEL        &none           &none
            &kp AT_RUS     &kp AMPS_RUS       &kp LBKT_RUS      &kp RBKT_RUS       &kp PLUS_RUS                        &kp PRCNT_RUS  &kp COLON_RUS  &kp SEMI_RUS   &none     &none      &none               &none           &none           &none          &none           &none
            >;
        };

        num {
            bindings = <
            &none          &none         &none         &none          &none                                                                                                      &none     &none      &none           &none      &none
            &none          &none         &none         &none          &none          &none                                                                       &none           &kp CARET &kp K      &kp J           &none      &none
            &none          &none         &none         &none          &none          &none                                                                       &kp STAR        &kp N7    &kp N8     &kp N9          &kp LS(G)  &kp E
            &none          &none         &kp TAB       &kp RET        &kp SPACE      &none                                                                       &kp PLUS        &kp N4    &kp N5     &kp N6          &kp MINUS  &none
            &none          &none         &none         &none          &none          &none   &trans  &trans          &none      &none      &none    &kp EQUAL    &kp PRCNT       &kp N1    &kp N2     &kp N3          &kp SLASH  &none
            &none          &none         &trans        &trans         &trans                 &trans  &sk_qrel LSFT   &tog NUM   &kp COMMA  &kp DOT  &kp N0                       &kp UNDER &kp RPAR   &kp LPAR        &none      &none
            >;
        };

        num_rus {
            bindings = <
            &none          &none         &none         &none          &none                                                                                                                 &none         &none          &none           &none          &none
            &none          &none         &none         &none          &none          &none                                                                                  &none           &kp CARET_RUS &kp K          &kp J           &none          &none
            &none          &none         &none         &none          &none          &none                                                                                  &kp STAR_RUS    &kp N7        &kp N8         &kp N9          &kp LS(G)      &kp E
            &none          &none         &kp TAB       &kp RET        &kp SPACE      &none                                                                                  &kp PLUS_RUS    &kp N4        &kp N5         &kp N6          &kp MINUS_RUS  &none
            &none          &none         &none         &none          &none          &none   &trans  &trans         &none      &none          &none        &kp EQUAL_RUS    &kp PRCNT_RUS   &kp N1        &kp N2         &kp N3          &kp SLASH_RUS  &none
            &none          &none         &trans        &trans         &trans                 &trans  &sk_qrel LSFT  &tog NUM   &kp COMMA_RUS  &kp DOT_RUS  &kp N0                           &kp UNDER_RUS &kp RPAR_RUS   &kp LPAR_RUS    &none          &none
            >;
        };

        fun {
            bindings = <
            &none          &none   &none         &none               &none                                                                                                                      &none            &none               &none         &none          &none
            &none          &none   &none         &kp LS(_C(RA(F4)))  &none             &none                                                                                     &none          &kp LG(EQUAL)    &kp LG(MINUS)       &kp LG(N0)    &none          &none
            &none          &none   &kp C_PWR     &kp _C(F2)          &kp LS(LC(D))     &none                                                                                     &kp C_BRI_UP   &kp F7           &kp F8              &kp F9        &kp F10        &none
            &none          &none   &kp TAB       &kp RET             &kp SPACE         &none                                                                                     &kp C_BRI_DN   &kp F4           &kp F5              &kp F6        &kp F11        &none
            &none          &none   &none         &none               &none             &none   &trans  &trans          &none      &kp C_PREV  &kp C_NEXT    &kp C_PP             &kp LG(LS(N5)) &kp F1           &kp F2              &kp F3        &kp F12        &none
            &none          &none   &trans        &trans              &trans                    &trans  &sk_qrel LSFT   &tog FUN   &kp C_MUTE  &kp C_VOL_DN  &kp C_VOL_UP                        &kp _C(F8)       &kp LS(RA(_C(F8)))  &kp _C(F4)    &kp _C(LS(F4)) &none
            >;
        };

        magic {
            bindings = <
            &bt BT_CLR        &none               &none           &none           &none                                                                                                           &none      &none      &none      &none      &bt BT_CLR_ALL
            &none             &none               &none           &none           &none           &none                                                                                &none      &none      &none      &none      &none      &none
            &none             &rgb_ug RGB_SPI     &rgb_ug RGB_SAI &rgb_ug RGB_HUI &rgb_ug RGB_BRI &rgb_ug RGB_TOG                                                                      &none      &none      &none      &none      &none      &none
            &bootloader       &rgb_ug RGB_SPD     &rgb_ug RGB_SAD &rgb_ug RGB_HUD &rgb_ug RGB_BRD &rgb_ug RGB_EFF                                                                      &none      &none      &none      &none      &none      &bootloader
            &sys_reset        &none               &none           &none           &none           &none           &bt_2     &bt_3     &none            &none     &none     &none       &none      &none      &none      &none      &none      &sys_reset
            &none             &none               &none           &none           &none                           &bt_0     &bt_1     &out OUT_USB     &none     &none     &none                  &none      &none      &none      &none      &none
            >;
        };
    };
};
